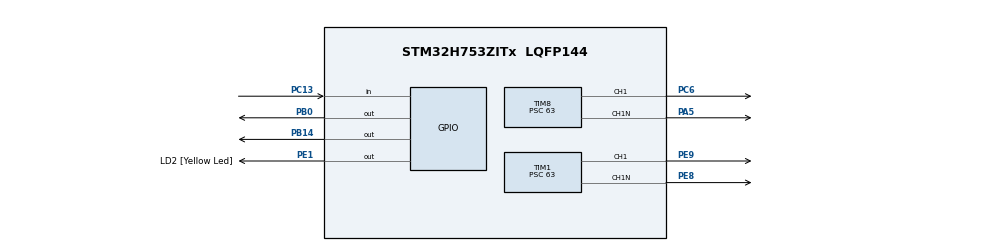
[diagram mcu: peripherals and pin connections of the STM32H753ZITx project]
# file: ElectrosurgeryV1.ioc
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CORTEX_M7.CPU_DCache=Disabled
CORTEX_M7.CPU_ICache=Disabled
CORTEX_M7.MPU_Control=__NULL
CORTEX_M7.default_mode_Activation=1
Mcu.Family=STM32H7
Mcu.Name=STM32H753ZITx
Mcu.Package=LQFP144
NUCLEO-H753ZI.BUTTON=1
NUCLEO-H753ZI.LD1=true
NUCLEO-H753ZI.LD2=true
NUCLEO-H753ZI.LD3=true
NUCLEO-H753ZI.VCP=true
NVIC.EXTI15_10_IRQn=true\:0\:0\:false\:false\:true\:false\:true\:true
NVIC.PriorityGroup=NVIC_PRIORITYGROUP_4
PA5.GPIO_PuPd=GPIO_PULLDOWN
PA5.Mode=PWM Generation1 CH1 CH1N
PA5.Signal=TIM8_CH1N
PB0.Signal=GPIO_Output
PB14.Signal=GPIO_Output
PC13.Signal=GPIO_Input
PC14-OSC32_IN\ (OSC32_IN).Signal=RCC_OSC32_IN
PC15-OSC32_OUT\ (OSC32_OUT).Signal=RCC_OSC32_OUT
PC6.GPIO_PuPd=GPIO_PULLDOWN
PC6.Signal=S_TIM8_CH1
PD8.Signal=USART3_TX
PD9.Signal=USART3_RX
PE1.GPIO_Label=LD2 [Yellow Led]
PE1.Signal=GPIO_Output
PE8.GPIO_PuPd=GPIO_PULLDOWN
PE8.Mode=PWM Generation1 CH1 CH1N
PE8.Signal=TIM1_CH1N
PE9.GPIO_PuPd=GPIO_PULLDOWN
PE9.Signal=S_TIM1_CH1
PH0-OSC_IN\ (PH0).Signal=RCC_OSC_IN
PH1-OSC_OUT\ (PH1).Signal=RCC_OSC_OUT
ProjectManager.HeapSize=0x200
ProjectManager.StackSize=0x400
ProjectManager.TargetToolchain=CMake
RCC.ADCFreq_Value=60000000
RCC.APB1Freq_Value=64000000
RCC.APB2Freq_Value=64000000
RCC.APB3Freq_Value=64000000
RCC.APB4Freq_Value=64000000
RCC.CortexFreq_Value=64000000
RCC.DIVM1=1
RCC.DIVM2=4
RCC.DIVN1=24
RCC.DIVN2=11
RCC.DIVP2=3
RCC.DIVQ1=4
RCC.HCLKFreq_Value=64000000
RCC.HSE_VALUE=8000000
RCC.PLL2FRACN=2048
RCC.PLLFRACN=0
RCC.PWR_Regulator_Voltage_Scale=PWR_REGULATOR_VOLTAGE_SCALE2
RCC.SYSCLKFreq_VALUE=64000000
RCC.USBFreq_Value=384000000
SH.S_TIM1_CH1.0=TIM1_CH1,PWM Generation1 CH1 CH1N
SH.S_TIM8_CH1.0=TIM8_CH1,PWM Generation1 CH1 CH1N
TIM1.Channel-Output\ Compare2\ No\ Output=TIM_CHANNEL_2
TIM1.Channel-PWM\ Generation1\ CH1\ CH1N=TIM_CHANNEL_1
TIM1.DeadTime=100
TIM1.OCMode_2=TIM_OCMODE_ACTIVE
TIM1.Period=1000
TIM1.Prescaler=63
TIM1.Pulse-Output\ Compare2\ No\ Output=300
TIM1.Pulse-PWM\ Generation1\ CH1\ CH1N=500
TIM1.TIM_MasterOutputTrigger=TIM_TRGO_OC2REF
TIM1.TIM_MasterSlaveMode=TIM_MASTERSLAVEMODE_DISABLE
TIM8.Channel-PWM\ Generation1\ CH1\ CH1N=TIM_CHANNEL_1
TIM8.DeadTime=100
TIM8.Period=1000
TIM8.Prescaler=63
TIM8.Pulse-PWM\ Generation1\ CH1\ CH1N=500
VP_MEMORYMAP_VS_MEMORYMAP.Mode=CurAppReg
VP_NUCLEO-H753ZI_VS_BSP_COMMON.Mode=COMMON
VP_TIM1_VS_ClockSourceINT.Mode=Internal
VP_TIM1_VS_no_output2.Mode=Output Compare2 No Output
VP_TIM8_VS_ClockSourceINT.Mode=Internal
VP_TIM8_VS_ClockSourceITR.Mode=TriggerSource_ITR0
VP_TIM8_VS_ControllerModeTrigger.Mode=Trigger Mode
board=NUCLEO-H753ZI

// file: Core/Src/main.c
/* USER CODE BEGIN Header */
/**
  ******************************************************************************
  * @file           : main.c
  * @brief          : Main program body
  ******************************************************************************
  * @attention
  *
  * Copyright (c) 2025 STMicroelectronics.
  * All rights reserved.
  *
  * This software is licensed under terms that can be found in the LICENSE file
  * in the root directory of this software component.
  * If no LICENSE file comes with this software, it is provided AS-IS.
  *
  ******************************************************************************
  */
/* USER CODE END Header */
#include "main.h"

COM_InitTypeDef BspCOMInit;

TIM_HandleTypeDef htim1;
TIM_HandleTypeDef htim8;

void SystemClock_Config(void);
static void MX_GPIO_Init(void);
static void MX_TIM1_Init(void);
static void MX_TIM8_Init(void);

int main(void)
{

  /* MCU Configuration--------------------------------------------------------*/

  /* Reset of all peripherals, Initializes the Flash interface and the Systick. */
  HAL_Init();

  /* Configure the system clock */
  SystemClock_Config();

  /* Initialize all configured peripherals */
  MX_GPIO_Init();
  MX_TIM1_Init();
  MX_TIM8_Init();

  /* Initialize leds */
  BSP_LED_Init(LED_GREEN);
  BSP_LED_Init(LED_BLUE);
  BSP_LED_Init(LED_RED);

  /* Initialize USER push-button, will be used to trigger an interrupt each time it's pressed.*/
  BSP_PB_Init(BUTTON_USER, BUTTON_MODE_EXTI);

  /* Initialize COM1 port (115200, 8 bits (7-bit data + 1 stop bit), no parity */
  BspCOMInit.BaudRate   = 115200;
  BspCOMInit.WordLength = COM_WORDLENGTH_8B;
  BspCOMInit.StopBits   = COM_STOPBITS_1;
  BspCOMInit.Parity     = COM_PARITY_NONE;
  BspCOMInit.HwFlowCtl  = COM_HWCONTROL_NONE;
  if (BSP_COM_Init(COM1, &BspCOMInit) != BSP_ERROR_NONE)
  {
    Error_Handler();
  }

  /* Infinite loop */
  /* USER CODE BEGIN WHILE */

  //TIM1->CCR2 = 300;

  HAL_TIM_PWM_Start(&htim1, TIM_CHANNEL_1);
  HAL_TIMEx_PWMN_Start(&htim1, TIM_CHANNEL_1);
  HAL_TIM_OC_Start(&htim1, TIM_CHANNEL_2);
  HAL_TIM_PWM_Start(&htim8, TIM_CHANNEL_1);
  HAL_TIMEx_PWMN_Start(&htim8, TIM_CHANNEL_1);

  //__HAL_TIM_SET_COMPARE(&htim1, TIM_CHANNEL_2, 500);

  //HAL_Delay(100);

  //__HAL_TIM_SET_COMPARE(&htim1, TIM_CHANNEL_2, 500);

  //__HAL_TIM_SET_COMPARE(&htim1, TIM_CHANNEL_2, 300);

  while (1)
  {

    HAL_GPIO_WritePin(LED1_GPIO_PORT, LED1_PIN, 1);

    HAL_Delay(100);

    //__HAL_TIM_SET_COMPARE(&htim1, TIM_CHANNEL_2, 300);

    HAL_GPIO_WritePin(LED1_GPIO_PORT, LED1_PIN, 0);

    HAL_Delay(100);

    // __HAL_TIM_SET_COMPARE(&htim1, TIM_CHANNEL_2, 500);

    /* USER CODE END WHILE */

  }
}

void SystemClock_Config(void)
{
  RCC_OscInitTypeDef RCC_OscInitStruct = {0};
  RCC_ClkInitTypeDef RCC_ClkInitStruct = {0};

  /** Supply configuration update enable
  */
  HAL_PWREx_ConfigSupply(PWR_LDO_SUPPLY);

  /** Configure the main internal regulator output voltage
  */
  __HAL_PWR_VOLTAGESCALING_CONFIG(PWR_REGULATOR_VOLTAGE_SCALE2);

  while(!__HAL_PWR_GET_FLAG(PWR_FLAG_VOSRDY)) {}

  /** Initializes the RCC Oscillators according to the specified parameters
  * in the RCC_OscInitTypeDef structure.
  */
  RCC_OscInitStruct.OscillatorType = RCC_OSCILLATORTYPE_HSI;
  RCC_OscInitStruct.HSIState = RCC_HSI_DIV1;
  RCC_OscInitStruct.HSICalibrationValue = RCC_HSICALIBRATION_DEFAULT;
  RCC_OscInitStruct.PLL.PLLState = RCC_PLL_NONE;
  if (HAL_RCC_OscConfig(&RCC_OscInitStruct) != HAL_OK)
  {
    Error_Handler();
  }

  /** Initializes the CPU, AHB and APB buses clocks
  */
  RCC_ClkInitStruct.ClockType = RCC_CLOCKTYPE_HCLK|RCC_CLOCKTYPE_SYSCLK
                              |RCC_CLOCKTYPE_PCLK1|RCC_CLOCKTYPE_PCLK2
                              |RCC_CLOCKTYPE_D3PCLK1|RCC_CLOCKTYPE_D1PCLK1;
  RCC_ClkInitStruct.SYSCLKSource = RCC_SYSCLKSOURCE_HSI;
  RCC_ClkInitStruct.SYSCLKDivider = RCC_SYSCLK_DIV1;
  RCC_ClkInitStruct.AHBCLKDivider = RCC_HCLK_DIV1;
  RCC_ClkInitStruct.APB3CLKDivider = RCC_APB3_DIV1;
  RCC_ClkInitStruct.APB1CLKDivider = RCC_APB1_DIV1;
  RCC_ClkInitStruct.APB2CLKDivider = RCC_APB2_DIV1;
  RCC_ClkInitStruct.APB4CLKDivider = RCC_APB4_DIV1;

  if (HAL_RCC_ClockConfig(&RCC_ClkInitStruct, FLASH_LATENCY_1) != HAL_OK)
  {
    Error_Handler();
  }
}

static void MX_TIM1_Init(void)
{

  TIM_ClockConfigTypeDef sClockSourceConfig = {0};
  TIM_MasterConfigTypeDef sMasterConfig = {0};
  TIM_OC_InitTypeDef sConfigOC = {0};
  TIM_BreakDeadTimeConfigTypeDef sBreakDeadTimeConfig = {0};

  htim1.Instance = TIM1;
  htim1.Init.Prescaler = 63;
  htim1.Init.CounterMode = TIM_COUNTERMODE_UP;
  htim1.Init.Period = 1000;
  htim1.Init.ClockDivision = TIM_CLOCKDIVISION_DIV1;
  htim1.Init.RepetitionCounter = 0;
  htim1.Init.AutoReloadPreload = TIM_AUTORELOAD_PRELOAD_DISABLE;
  if (HAL_TIM_Base_Init(&htim1) != HAL_OK)
  {
    Error_Handler();
  }
  sClockSourceConfig.ClockSource = TIM_CLOCKSOURCE_INTERNAL;
  if (HAL_TIM_ConfigClockSource(&htim1, &sClockSourceConfig) != HAL_OK)
  {
    Error_Handler();
  }
  if (HAL_TIM_PWM_Init(&htim1) != HAL_OK)
  {
    Error_Handler();
  }
  if (HAL_TIM_OC_Init(&htim1) != HAL_OK)
  {
    Error_Handler();
  }
  sMasterConfig.MasterOutputTrigger = TIM_TRGO_OC2REF;
  sMasterConfig.MasterOutputTrigger2 = TIM_TRGO2_RESET;
  sMasterConfig.MasterSlaveMode = TIM_MASTERSLAVEMODE_DISABLE;
  if (HAL_TIMEx_MasterConfigSynchronization(&htim1, &sMasterConfig) != HAL_OK)
  {
    Error_Handler();
  }
  sConfigOC.OCMode = TIM_OCMODE_PWM1;
  sConfigOC.Pulse = 500;
  sConfigOC.OCPolarity = TIM_OCPOLARITY_HIGH;
  sConfigOC.OCNPolarity = TIM_OCNPOLARITY_HIGH;
  sConfigOC.OCFastMode = TIM_OCFAST_DISABLE;
  sConfigOC.OCIdleState = TIM_OCIDLESTATE_RESET;
  sConfigOC.OCNIdleState = TIM_OCNIDLESTATE_RESET;
  if (HAL_TIM_PWM_ConfigChannel(&htim1, &sConfigOC, TIM_CHANNEL_1) != HAL_OK)
  {
    Error_Handler();
  }
  sConfigOC.OCMode = TIM_OCMODE_ACTIVE;
  sConfigOC.Pulse = 300;
  if (HAL_TIM_OC_ConfigChannel(&htim1, &sConfigOC, TIM_CHANNEL_2) != HAL_OK)
  {
    Error_Handler();
  }
  sBreakDeadTimeConfig.OffStateRunMode = TIM_OSSR_DISABLE;
  sBreakDeadTimeConfig.OffStateIDLEMode = TIM_OSSI_DISABLE;
  sBreakDeadTimeConfig.LockLevel = TIM_LOCKLEVEL_OFF;
  sBreakDeadTimeConfig.DeadTime = 100;
  sBreakDeadTimeConfig.BreakState = TIM_BREAK_DISABLE;
  sBreakDeadTimeConfig.BreakPolarity = TIM_BREAKPOLARITY_HIGH;
  sBreakDeadTimeConfig.BreakFilter = 0;
  sBreakDeadTimeConfig.Break2State = TIM_BREAK2_DISABLE;
  sBreakDeadTimeConfig.Break2Polarity = TIM_BREAK2POLARITY_HIGH;
  sBreakDeadTimeConfig.Break2Filter = 0;
  sBreakDeadTimeConfig.AutomaticOutput = TIM_AUTOMATICOUTPUT_DISABLE;
  if (HAL_TIMEx_ConfigBreakDeadTime(&htim1, &sBreakDeadTimeConfig) != HAL_OK)
  {
    Error_Handler();
  }
  HAL_TIM_MspPostInit(&htim1);

}

static void MX_TIM8_Init(void)
{

  TIM_ClockConfigTypeDef sClockSourceConfig = {0};
  TIM_SlaveConfigTypeDef sSlaveConfig = {0};
  TIM_MasterConfigTypeDef sMasterConfig = {0};
  TIM_OC_InitTypeDef sConfigOC = {0};
  TIM_BreakDeadTimeConfigTypeDef sBreakDeadTimeConfig = {0};

  htim8.Instance = TIM8;
  htim8.Init.Prescaler = 63;
  htim8.Init.CounterMode = TIM_COUNTERMODE_UP;
  htim8.Init.Period = 1000;
  htim8.Init.ClockDivision = TIM_CLOCKDIVISION_DIV1;
  htim8.Init.RepetitionCounter = 0;
  htim8.Init.AutoReloadPreload = TIM_AUTORELOAD_PRELOAD_DISABLE;
  if (HAL_TIM_Base_Init(&htim8) != HAL_OK)
  {
    Error_Handler();
  }
  sClockSourceConfig.ClockSource = TIM_CLOCKSOURCE_INTERNAL;
  if (HAL_TIM_ConfigClockSource(&htim8, &sClockSourceConfig) != HAL_OK)
  {
    Error_Handler();
  }
  if (HAL_TIM_PWM_Init(&htim8) != HAL_OK)
  {
    Error_Handler();
  }
  sSlaveConfig.SlaveMode = TIM_SLAVEMODE_TRIGGER;
  sSlaveConfig.InputTrigger = TIM_TS_ITR0;
  if (HAL_TIM_SlaveConfigSynchro(&htim8, &sSlaveConfig) != HAL_OK)
  {
    Error_Handler();
  }
  sMasterConfig.MasterOutputTrigger = TIM_TRGO_RESET;
  sMasterConfig.MasterOutputTrigger2 = TIM_TRGO2_RESET;
  sMasterConfig.MasterSlaveMode = TIM_MASTERSLAVEMODE_DISABLE;
  if (HAL_TIMEx_MasterConfigSynchronization(&htim8, &sMasterConfig) != HAL_OK)
  {
    Error_Handler();
  }
  sConfigOC.OCMode = TIM_OCMODE_PWM1;
  sConfigOC.Pulse = 500;
  sConfigOC.OCPolarity = TIM_OCPOLARITY_HIGH;
  sConfigOC.OCNPolarity = TIM_OCNPOLARITY_HIGH;
  sConfigOC.OCFastMode = TIM_OCFAST_DISABLE;
  sConfigOC.OCIdleState = TIM_OCIDLESTATE_RESET;
  sConfigOC.OCNIdleState = TIM_OCNIDLESTATE_RESET;
  if (HAL_TIM_PWM_ConfigChannel(&htim8, &sConfigOC, TIM_CHANNEL_1) != HAL_OK)
  {
    Error_Handler();
  }
  sBreakDeadTimeConfig.OffStateRunMode = TIM_OSSR_DISABLE;
  sBreakDeadTimeConfig.OffStateIDLEMode = TIM_OSSI_DISABLE;
  sBreakDeadTimeConfig.LockLevel = TIM_LOCKLEVEL_OFF;
  sBreakDeadTimeConfig.DeadTime = 100;
  sBreakDeadTimeConfig.BreakState = TIM_BREAK_DISABLE;
  sBreakDeadTimeConfig.BreakPolarity = TIM_BREAKPOLARITY_HIGH;
  sBreakDeadTimeConfig.BreakFilter = 0;
  sBreakDeadTimeConfig.Break2State = TIM_BREAK2_DISABLE;
  sBreakDeadTimeConfig.Break2Polarity = TIM_BREAK2POLARITY_HIGH;
  sBreakDeadTimeConfig.Break2Filter = 0;
  sBreakDeadTimeConfig.AutomaticOutput = TIM_AUTOMATICOUTPUT_DISABLE;
  if (HAL_TIMEx_ConfigBreakDeadTime(&htim8, &sBreakDeadTimeConfig) != HAL_OK)
  {
    Error_Handler();
  }
  HAL_TIM_MspPostInit(&htim8);

}

static void MX_GPIO_Init(void)
{
  GPIO_InitTypeDef GPIO_InitStruct = {0};

  /* GPIO Ports Clock Enable */
  __HAL_RCC_GPIOC_CLK_ENABLE();
  __HAL_RCC_GPIOH_CLK_ENABLE();
  __HAL_RCC_GPIOA_CLK_ENABLE();
  __HAL_RCC_GPIOE_CLK_ENABLE();

  /*Configure GPIO pin Output Level */
  HAL_GPIO_WritePin(LD2_GPIO_Port, LD2_Pin, GPIO_PIN_RESET);

  /*Configure GPIO pin : LD2_Pin */
  GPIO_InitStruct.Pin = LD2_Pin;
  GPIO_InitStruct.Mode = GPIO_MODE_OUTPUT_PP;
  GPIO_InitStruct.Pull = GPIO_NOPULL;
  GPIO_InitStruct.Speed = GPIO_SPEED_FREQ_LOW;
  HAL_GPIO_Init(LD2_GPIO_Port, &GPIO_InitStruct);

}

void Error_Handler(void)
{
  __disable_irq();
  while (1)
  {
  }
}
